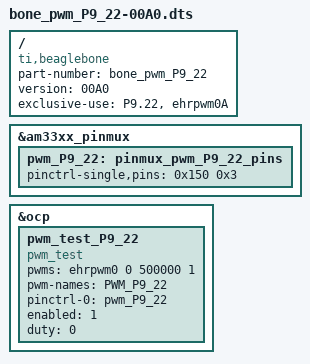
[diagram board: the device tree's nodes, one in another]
/*
 * Copyright (C) 2013 CircuitCo
 * Copyright (C) 2013 Texas Instruments
 *
 * This program is free software; you can redistribute it and/or modify
 * it under the terms of the GNU General Public License version 2 as
 * published by the Free Software Foundation.
 */
/dts-v1/;
/plugin/;

/ {
	compatible = "ti,beaglebone", "ti,beaglebone-black";

	/* identification */
	part-number = "bone_pwm_P9_22";
	version = "00A0";

	/* state the resources this cape uses */
	exclusive-use =
		/* the pin header uses */
		"P9.22",		/* pwm: ehrpwm0A */
		/* the hardware IP uses */
		"ehrpwm0A";

	fragment@0 {
		target = <&am33xx_pinmux>;
		__overlay__ {
			pwm_P9_22: pinmux_pwm_P9_22_pins {
				pinctrl-single,pins = <0x150  0x3>; /* P9_22 (ZCZ ball A17) | MODE 3 */
			};
		};
	};

	fragment@1 {
		target = <&ocp>;
		__overlay__ {
			pwm_test_P9_22 {
				compatible	= "pwm_test";
				pwms 		= <&ehrpwm0 0 500000 1>;
				pwm-names 	= "PWM_P9_22";
			    pinctrl-names	= "default";
			    pinctrl-0	= <&pwm_P9_22>;
				enabled		= <1>;
				duty		= <0>;
				status 		= "okay";
			};
		};
	};
};
